# CY8C5888LTI_LP097 register map
File version: 0.1
Registers are 8-bit, read-write, no defined reset value unless marked. A register's access mark holds for its fields unless they carry their own. Offsets are from the block's base; [hi:lo] are bit positions.

## RPi_SPIS
Base 0x00000000
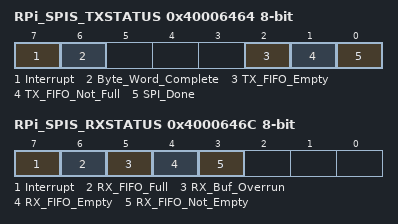
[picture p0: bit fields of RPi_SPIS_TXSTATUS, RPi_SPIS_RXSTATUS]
0x40006464 RPi_SPIS_TXSTATUS — SPIS TX Status Register
  [7] Interrupt ro — Set when interrupt occurs
  [6] Byte_Word_Complete ro — Set when a byte/word transmit has completed
  [2] TX_FIFO_Empty ro — Set when the TX Data FIFO is empty
  [1] TX_FIFO_Not_Full ro — Set when the TX Data FIFO is not full
  [0] SPI_Done ro — Set when all of the data in the transmit FIFO has been sent. Set when Byte/Word Complete has been set and TX Data FIFO is empty
0x4000646C RPi_SPIS_RXSTATUS — SPIS RX Status Register
  [7] Interrupt ro — Set when interrupt occurs
  [6] RX_FIFO_Full ro — Set when the RX Data FIFO is full
  [5] RX_Buf_Overrun ro — Set when RX Data has overrun the 4 byte/word FIFO without being moved to the RX buffer cmemory array (if one exists)
  [4] RX_FIFO_Empty ro — Set when the RX Data FIFO is empty
  [3] RX_FIFO_Not_Empty ro — Set when the RX Data FIFO is not empty. That is, at least one byte/word is in the RX FIFO
0x40006508 RPi_SPIS_RX_DATA — SPIS RX Data
0x40006508 RPi_SPIS_TX_DATA — SPIS TX Data

## I2C_1
Base 0x00000000
0x40006504 I2C_1_DATA — I2C Data Register
  [7:0] data — Read received data or write data to transmit.
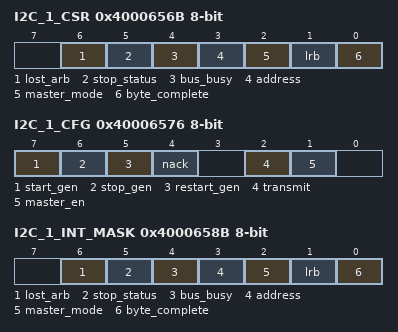
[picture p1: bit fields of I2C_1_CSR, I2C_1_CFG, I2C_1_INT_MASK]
0x4000656B I2C_1_CSR — I2C Status Register
  [6] lost_arb ro — If set, indicates arbitration was lost (multi-master and multi-master-slave modes).
  [5] stop_status ro — If set, indicates a Stop condition was detected on the bus.
  [4] bus_busy ro — If set, indicates the bus is busy. Data is currently being transmitted or received.
  [3] address ro — Address detection. If set, indicates that an address byte was sent.
  [2] master_mode ro — Indicates that a valid Start condition was generated and a hardware device is operating as bus master.
  [1] lrb ro — Last Received Bit. Indicates the state of the last received bit, which is the ACK/NAK received for the last byte transmitted. Cleared = ACK and set = NAK.
  [0] byte_complete ro — Transmit or receive status since the last read of this register. In Transmit mode this bit indicates that eight bits of data plus ACK/NAK have been transmitted since the last read. In Receive mode this bit indicates that eight bits of data have been received since the last read of this register.
0x40006576 I2C_1_CFG — I2C Configuration Register
  [7] start_gen — Set to 1 to generate a Start condition on the bus. This bit must be cleared by firmware before initiating the next transaction.
  [6] stop_gen — Set to 1 to generate a Stop condition on the bus. This bit must be cleared by firmware before initiating the next transaction.
  [5] restart_gen — Set to 1 to generate a Restart condition on the bus. This bit must be cleared by firmware after a Restart condition is generated.
  [4] nack — Set to 1 to NAK the next read byte. Clear to ACK next read byte. This bit must be cleared by firmware between bytes.
  [2] transmit — Set to 1 to set the current mode to transmit or clear to 0 to receive a byte of data. This bit must be cleared by firmware before starting the next transmit or receive transaction.
  [1] master_en — Set to 1 to enable the master functionality.
0x4000658B I2C_1_INT_MASK — I2C Interrupt Enable Mask
  [6] lost_arb — Enables interrupt from the corresponding bit in status register.
  [5] stop_status — Enables interrupt from the corresponding bit in status register.
  [4] bus_busy — Enables interrupt from the corresponding bit in status register.
  [3] address — Enables interrupt from the corresponding bit in status register.
  [2] master_mode — Enables interrupt from the corresponding bit in status register.
  [1] lrb — Enables interrupt from the corresponding bit in status register.
  [0] byte_complete — Enables interrupt from the corresponding bit in status register.

## I2C_2
Base 0x00000000
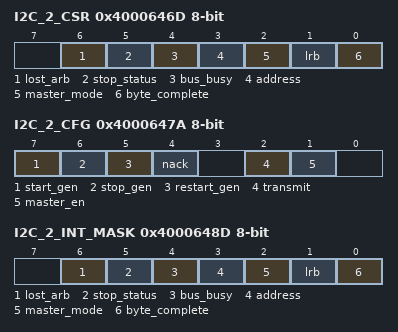
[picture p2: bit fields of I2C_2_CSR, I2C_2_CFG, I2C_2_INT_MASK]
0x4000646D I2C_2_CSR — I2C Status Register
  [6] lost_arb ro — If set, indicates arbitration was lost (multi-master and multi-master-slave modes).
  [5] stop_status ro — If set, indicates a Stop condition was detected on the bus.
  [4] bus_busy ro — If set, indicates the bus is busy. Data is currently being transmitted or received.
  [3] address ro — Address detection. If set, indicates that an address byte was sent.
  [2] master_mode ro — Indicates that a valid Start condition was generated and a hardware device is operating as bus master.
  [1] lrb ro — Last Received Bit. Indicates the state of the last received bit, which is the ACK/NAK received for the last byte transmitted. Cleared = ACK and set = NAK.
  [0] byte_complete ro — Transmit or receive status since the last read of this register. In Transmit mode this bit indicates that eight bits of data plus ACK/NAK have been transmitted since the last read. In Receive mode this bit indicates that eight bits of data have been received since the last read of this register.
0x4000647A I2C_2_CFG — I2C Configuration Register
  [7] start_gen — Set to 1 to generate a Start condition on the bus. This bit must be cleared by firmware before initiating the next transaction.
  [6] stop_gen — Set to 1 to generate a Stop condition on the bus. This bit must be cleared by firmware before initiating the next transaction.
  [5] restart_gen — Set to 1 to generate a Restart condition on the bus. This bit must be cleared by firmware after a Restart condition is generated.
  [4] nack — Set to 1 to NAK the next read byte. Clear to ACK next read byte. This bit must be cleared by firmware between bytes.
  [2] transmit — Set to 1 to set the current mode to transmit or clear to 0 to receive a byte of data. This bit must be cleared by firmware before starting the next transmit or receive transaction.
  [1] master_en — Set to 1 to enable the master functionality.
0x4000648D I2C_2_INT_MASK — I2C Interrupt Enable Mask
  [6] lost_arb — Enables interrupt from the corresponding bit in status register.
  [5] stop_status — Enables interrupt from the corresponding bit in status register.
  [4] bus_busy — Enables interrupt from the corresponding bit in status register.
  [3] address — Enables interrupt from the corresponding bit in status register.
  [2] master_mode — Enables interrupt from the corresponding bit in status register.
  [1] lrb — Enables interrupt from the corresponding bit in status register.
  [0] byte_complete — Enables interrupt from the corresponding bit in status register.
0x4000650A I2C_2_DATA — I2C Data Register
  [7:0] data — Read received data or write data to transmit.
